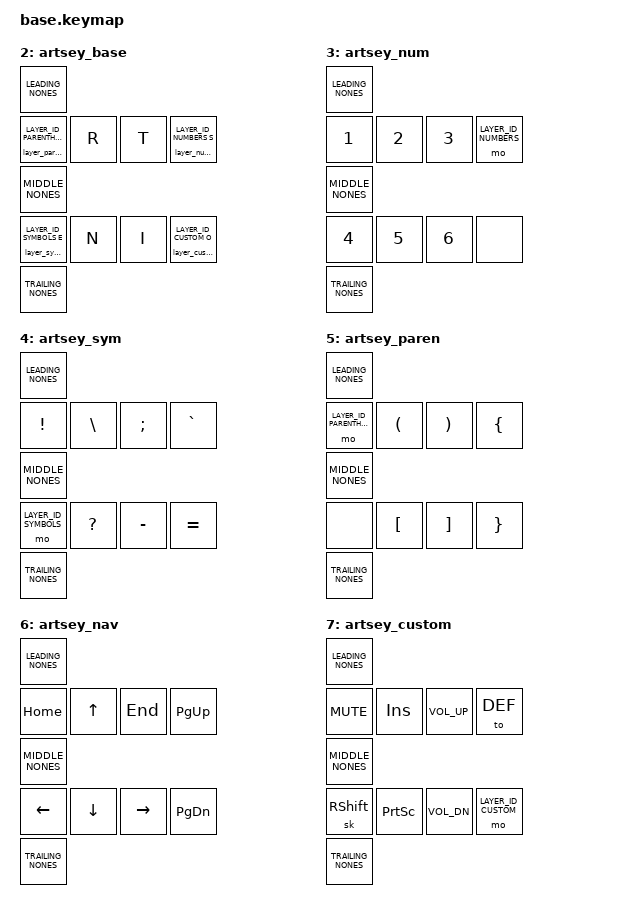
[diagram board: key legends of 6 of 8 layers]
/*
 * Copyright (c) 2020 The ZMK Contributors
 *
 * SPDX-License-Identifier: MIT
 */

#include <behaviors.dtsi>
#include <dt-bindings/zmk/keys.h>
#include <dt-bindings/zmk/bt.h>

#include "../zmk-nodefree-config/helper.h"

#define DEF 0
#define NUM 1
/*****************************************
 * Layer IDs used by the ARTSEY keymap
 * Do NOT change these and do NOT change the order of the layers as shown below
 *****************************************/
#define LAYER_ID_BASE 2
#define LAYER_ID_NUMBERS 3
#define LAYER_ID_SYMBOLS 4
#define LAYER_ID_PARENTHETICALS 5
#define LAYER_ID_NAVIGATION 6
#define LAYER_ID_CUSTOM 7

#define LAYERS_ARTSEY LAYER_ID_BASE LAYER_ID_NUMBERS LAYER_ID_SYMBOLS LAYER_ID_PARENTHETICALS LAYER_ID_NAVIGATION LAYER_ID_CUSTOM


#include "combos.dtsi"  // source after layer shortcuts

#if !defined EXTRA_MID
    #define EXTRA_MID
#endif
#if !defined EXTRA_BOT_L
    #define EXTRA_BOT_L
#endif
#if !defined EXTRA_BOT_R
    #define EXTRA_BOT_R
#endif

#define XXX &none
#define ___ &trans
#define PRS LS(LC(LG(N4)))

#define KEYS_L LT0 LT1 LT2 LT3 LT4 LM0 LM1 LM2 LM3 LM4 LB0 LB1 LB2 LB3 LB4  // left-hand keys
#define KEYS_R RT0 RT1 RT2 RT3 RT4 RM0 RM1 RM2 RM3 RM4 RB0 RB1 RB2 RB3 RB4  // right-hand keys
#define THUMBS LH2 LH1 LH0 RH0 RH1 RH2                                      // thumb keys

#if !defined TIMEOUT_LAYER_HOLD
#define TIMEOUT_LAYER_HOLD 200
#endif
#if !defined TIMEOUT_STICKY_LEADER_KEY
#define TIMEOUT_STICKY_LEADER_KEY 5000
#endif

&mt {
  //  flavor = "tap-preferred";
   // tapping_term_ms = <200>;
};

&sk {
	release-after-ms = <TIMEOUT_STICKY_LEADER_KEY>;
    quick-release;
};

ZMK_BEHAVIOR(hm, hold_tap,
   tapping-term-ms = <250>;
   quick-tap-ms = <200>;
   flavor = "tap-preferred";
   bindings = <&kp>, <&kp>;
)

ZMK_BEHAVIOR(lhm, hold_tap,
   flavor = "tap-preferred";
   tapping-term-ms = <250>;                        // <---[[produces tap if held longer than tapping-term-ms]]
   quick-tap-ms = <175>;
   global-quick-tap-ms = <150>;
   bindings = <&kp>, <&kp>;
   hold-trigger-key-positions = <5 6 7 8 9 15 16 17 18 19 25 26 27 28 29 32 33>;    // <---[[right-hand keys]]
   hold-trigger-on-release;
)

ZMK_BEHAVIOR(rhm, hold_tap,
   flavor = "tap-preferred";
   tapping-term-ms = <250>;                        // <---[[produces tap if held longer than tapping-term-ms]]
   quick-tap-ms = <175>;
   global-quick-tap-ms = <150>;
   bindings = <&kp>, <&kp>;
   hold-trigger-key-positions = <0 1 2 3 4 10 11 12 13 14 20 21 22 23 24 30 31>;    // <---[[left-hand keys]]
   hold-trigger-on-release;
)

ZMK_BEHAVIOR(tdreset, tap_dance,
   tapping-term-ms = <200>;
   bindings = <&kp TILDE>, <&bootloader>;
)

ZMK_BEHAVIOR(layer_base_kp, hold_tap,
   flavor = "tap-preferred";
   tapping_term_ms = <TIMEOUT_LAYER_HOLD>;
   bindings = <&mo>, <&kp>;
)

ZMK_BEHAVIOR(layer_numbers_kp, hold_tap,
   flavor = "tap-preferred";
   tapping_term_ms = <TIMEOUT_LAYER_HOLD>;
   bindings = <&mo>, <&kp>;
)

ZMK_BEHAVIOR(layer_symbols_kp, hold_tap,
   flavor = "tap-preferred";
   tapping_term_ms = <TIMEOUT_LAYER_HOLD>;
   bindings = <&mo>, <&kp>;
)

ZMK_BEHAVIOR(layer_parentheticals_kp, hold_tap,
   flavor = "tap-preferred";
   tapping_term_ms = <TIMEOUT_LAYER_HOLD>;
   bindings = <&mo>, <&kp>;
)

ZMK_BEHAVIOR(layer_custom_kp, hold_tap,
   flavor = "tap-preferred";
   tapping_term_ms = <TIMEOUT_LAYER_HOLD>;
   bindings = <&mo>, <&kp>;
)

ZMK_LAYER(default_layer,
     // ╭─────────────┬─────────────┬─────────────┬─────────────┬─────────────╮   ╭─────────────╮   ╭─────────────┬─────────────┬─────────────┬─────────────┬─────────────╮
          &kp SEMI      &kp COMMA     &kp DOT       &kp P         &kp Y             EXTRA_MID         &kp F         &kp G         &kp C         &kp R         &kp L
     // ├─────────────┼─────────────┼─────────────┼─────────────┼─────────────┤   ├─────────────┤   ├─────────────┼─────────────┼─────────────┼─────────────┼─────────────┤
          &kp A         &lhm LCTRL O  &lhm LALT E   &lhm LGUI U   &kp I             EXTRA_MID         &kp D         &rhm RGUI H   &rhm RALT T   &rhm RCTRL N  &kp S
     // ├─────────────┼─────────────┼─────────────┼─────────────┼─────────────┤   ├─────────────┤   ├─────────────┼─────────────┼─────────────┼─────────────┼─────────────┤
          &kp APOS      &kp Q         &kp J         &kp K         &kp X             EXTRA_MID         &kp B         &kp M         &kp W         &kp V         &kp Z
     // ├─────────────┼─────────────┼─────────────┼─────────────┼─────────────┤   ├─────────────┤   ├─────────────┼─────────────┼─────────────┼─────────────┼─────────────┤
          EXTRA_BOT_L                          &hm LC(LS(LALT)) SPC &sk LSHFT       EXTRA_MID         &kp BSPC      &to NUM                                   EXTRA_BOT_R
     // ╰─────────────╯                           ╰─────────────┴─────────────╯   ╰─────────────╯   ╰─────────────┴─────────────╯                           ╰─────────────╯
)

ZMK_LAYER(num_layer,
     // ╭─────────────┬─────────────┬─────────────┬─────────────┬─────────────╮   ╭─────────────╮   ╭─────────────┬─────────────┬─────────────┬─────────────┬─────────────╮
          &kp ESC       &kp HOME      &kp UP        &kp END       &kp PG_UP         EXTRA_MID        &hm F12 COMMA  &hm F7 N7     &hm F8 N8     &hm F9 N9     &kp BKSP
     // ├─────────────┼─────────────┼─────────────┼─────────────┼─────────────┤   ├─────────────┤   ├─────────────┼─────────────┼─────────────┼─────────────┼─────────────┤
          &kp TAB       &kp LEFT      &kp DOWN      &kp RIGHT     &kp PG_DN         EXTRA_MID        &hm F11 DOT    &hm F4 N4     &hm F5 N5     &hm F6 N6     &kp RET
     // ├─────────────┼─────────────┼─────────────┼─────────────┼─────────────┤   ├─────────────┤   ├─────────────┼─────────────┼─────────────┼─────────────┼─────────────┤
          &kp C_BRI_DN &kp C_BRI_UP  &kp C_VOL_DN   &kp C_VOL_UP  &kp RALT          EXTRA_MID         &hm F10 N0    &hm F1 N1     &hm F2 N2     &hm F3 N3     &kp PRS
     // ├─────────────┼─────────────┼─────────────┼─────────────┼─────────────┤   ├─────────────┤   ├─────────────┼─────────────┼─────────────┼─────────────┼─────────────┤
          EXTRA_BOT_L                               &to DEF       &sk LSHFT         EXTRA_MID         &kp RGUI      XXX                                       EXTRA_BOT_R
     // ╰─────────────╯                           ╰─────────────┴─────────────╯   ╰─────────────╯   ╰─────────────┴─────────────╯                           ╰─────────────╯
)

/*****************************************
 * Macros for filling in "&none" in the right places in the keymap for re-use needs
 *****************************************/
#define NONE0(X)
#define NONE1(X) X
#define NONE2(X) NONE1(X) X
#define NONE3(X) NONE2(X) X
#define NONE4(X) NONE3(X) X
#define NONE5(X) NONE4(X) X
#define NONE6(X) NONE5(X) X
#define NONE7(X) NONE6(X) X
#define NONE8(X) NONE7(X) X
#define NONE9(X) NONE8(X) X
#define NONE10(X) NONE9(X) X

#define NONE(HUNDREDS,TENS,ONES) \
  NONE##HUNDREDS(NONE10(NONE10(&none))) \
  NONE##TENS(NONE10(&none)) \
  NONE##ONES(&none)

ZMK_LAYER(artsey_base,
     LEADING_NONES
     &layer_parentheticals_kp LAYER_ID_PARENTHETICALS A  &kp R     &kp T     &layer_numbers_kp LAYER_ID_NUMBERS S
     MIDDLE_NONES
     &layer_symbols_kp LAYER_ID_SYMBOLS E                &kp N     &kp I     &layer_custom_kp LAYER_ID_CUSTOM O
     TRAILING_NONES
)

ZMK_LAYER(artsey_num,
				LEADING_NONES
				&kp N1                                              &kp N2    &kp N3    &mo LAYER_ID_NUMBERS
				MIDDLE_NONES
				&kp N4                                              &kp N5    &kp N6    &none
				TRAILING_NONES
)

ZMK_LAYER(artsey_sym,
				LEADING_NONES
				&kp EXCL                                            &kp BSLH  &kp SEMI  &kp GRAVE
				MIDDLE_NONES
				&mo LAYER_ID_SYMBOLS                                &kp QMARK &kp MINUS &kp EQUAL
				TRAILING_NONES
)

ZMK_LAYER(artsey_paren,
				LEADING_NONES
				&mo LAYER_ID_PARENTHETICALS                         &kp LPAR  &kp RPAR  &kp LBRC
				MIDDLE_NONES
				&none                                               &kp LBKT  &kp RBKT  &kp RBRC
				TRAILING_NONES
)

ZMK_LAYER(artsey_nav,
				LEADING_NONES
				&kp HOME                                            &kp UP    &kp END   &kp PG_UP
				MIDDLE_NONES
				&kp LEFT                                            &kp DOWN  &kp RIGHT &kp PG_DN
				TRAILING_NONES
)

ZMK_LAYER(artsey_custom,
				LEADING_NONES
				&kp C_MUTE &kp INS   &kp C_VOL_UP  &to DEF
				MIDDLE_NONES
				&sk RSHFT  &kp PSCRN &kp C_VOL_DN  &mo LAYER_ID_CUSTOM
				TRAILING_NONES
)
